VERSION "DBC_EMP_PUMP"

NS_ :

BS_:

BU_:

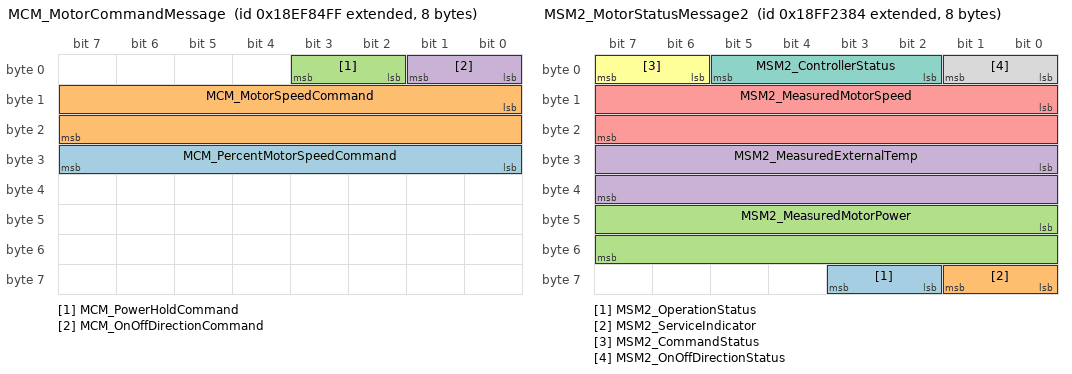
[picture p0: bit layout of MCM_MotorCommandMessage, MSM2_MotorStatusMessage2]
BO_ 2565833983 MCM_MotorCommandMessage: 8 Vector__XXX
 SG_ MCM_PercentMotorSpeedCommand : 24|8@1+ (0.5,0) [0|125] "%" Vector__XXX
 SG_ MCM_MotorSpeedCommand : 8|16@1+ (0.5,0) [0|32127.5] "rpm" Vector__XXX
 SG_ MCM_PowerHoldCommand : 2|2@1+ (1,0) [0|3] "" Vector__XXX
 SG_ MCM_OnOffDirectionCommand : 0|2@1+ (1,0) [0|3] "" Vector__XXX

BO_ 2566857604 MSM2_MotorStatusMessage2: 8 Vector__XXX
 SG_ MSM2_OperationStatus : 58|2@1+ (1,0) [0|3] "" Vector__XXX
 SG_ MSM2_ServiceIndicator : 56|2@1+ (1,0) [0|3] "" Vector__XXX
 SG_ MSM2_MeasuredMotorPower : 40|16@1+ (0.5,0) [0|32127.5] "W" Vector__XXX
 SG_ MSM2_MeasuredExternalTemp : 24|16@1+ (0.03125,-273) [-273|1734.96875] "C" Vector__XXX
 SG_ MSM2_MeasuredMotorSpeed : 8|16@1+ (0.5,0) [0|32127.5] "rpm" Vector__XXX
 SG_ MSM2_CommandStatus : 6|2@1+ (1,0) [0|3] "" Vector__XXX
 SG_ MSM2_ControllerStatus : 2|4@1+ (1,0) [0|15] "" Vector__XXX
 SG_ MSM2_OnOffDirectionStatus : 0|2@1+ (1,0) [0|3] "" Vector__XXX

BA_DEF_ BO_  "GenMsgSendType" ENUM  "cyclic","reserved","cyclicIfActive","reserved","reserved","reserved","reserved","reserved","noMsgSendType";
BA_DEF_ BO_  "GenMsgCycleTime" INT 0 3600000;
BA_DEF_ BO_  "VFrameFormat" ENUM  "StandardCAN","ExtendedCAN","reserved","J1939PG";
BA_DEF_  "DBName" STRING ;
BA_DEF_  "BusType" STRING ;
BA_DEF_  "ProtocolType" STRING ;
BA_DEF_DEF_  "GenMsgSendType" "noMsgSendType";
BA_DEF_DEF_  "GenMsgCycleTime" 0;
BA_DEF_DEF_  "VFrameFormat" "J1939PG";
BA_DEF_DEF_  "DBName" "";
BA_DEF_DEF_  "BusType" "CAN";
BA_DEF_DEF_  "ProtocolType" "J1939";
BA_ "DBName" "EMP_Components";
BA_ "GenMsgCycleTime" BO_ 2565833983 1000;
BA_ "GenMsgSendType" BO_ 2565833983 0;
BA_ "GenMsgCycleTime" BO_ 2566857604 1000;
BA_ "GenMsgSendType" BO_ 2566857604 0;
VAL_ 2565833983 MCM_PowerHoldCommand 3 "Don't Care / Take No Action" 2 "Reserved" 1 "Power On" 0 "Power Off" ;
VAL_ 2565833983 MCM_OnOffDirectionCommand 3 "Don't Care / Take No Action" 2 "Motor On: Reverse Direction" 1 "Motor On: Normal/Dflt Direction" 0 "Motor Off" ;
VAL_ 2566857604 MSM2_OperationStatus 3 "Not Available" 2 "Not Operable" 1 "Derated Operation" 0 "Normal Operation" ;
VAL_ 2566857604 MSM2_ServiceIndicator 3 "Not Available" 2 "Reserved" 1 "Service Required" 0 "Service Not Required" ;
VAL_ 2566857604 MSM2_CommandStatus 3 "Not Available" 2 "Command is Default" 1 "Command is External" 0 "Command is Internal" ;
VAL_ 2566857604 MSM2_ControllerStatus 15 "Not Available" 14 "Reserved" 13 "Reserved" 12 "Reserved" 11 "Spd Limit By Over-Volt Protect" 10 "Reserved" 9 "Exceed Cmd Spd By Extrnal Forces" 8 "Spd Limit By Over-Temp Protect" 7 "Speed Limited By Torque Limit" 6 "Speed Limited By Max Capability" 5 "Speed Limited By Amperage Limit" 4 "Over-Temperature Protect Shutdn" 3 "Under-Voltage Protect Shutdn" 2 "Over-Voltage Protect Shutdn" 1 "Unable to Start" 0 "Normal Operation" ;
VAL_ 2566857604 MSM2_OnOffDirectionStatus 3 "Not Available" 2 "Motor On: Reverse Direction" 1 "Motor On: Normal/Dflt Direction" 0 "Motor Off" ;
